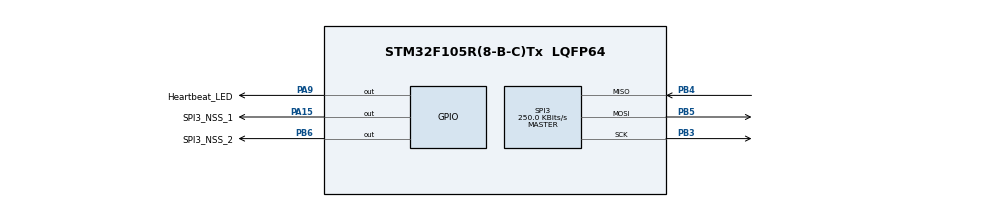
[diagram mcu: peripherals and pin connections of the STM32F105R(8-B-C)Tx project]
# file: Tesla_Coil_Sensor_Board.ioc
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Mcu.Family=STM32F1
Mcu.Name=STM32F105R(8-B-C)Tx
Mcu.Package=LQFP64
NVIC.PriorityGroup=NVIC_PRIORITYGROUP_4
NVIC.TIM2_IRQn=true\:0\:0\:false\:false\:true\:true\:true\:true
PA13.Mode=Serial_Wire
PA13.Signal=SYS_JTMS-SWDIO
PA14.Mode=Serial_Wire
PA14.Signal=SYS_JTCK-SWCLK
PA15.GPIO_Label=SPI3_NSS_1
PA15.Signal=GPIO_Output
PA9.GPIO_Label=Heartbeat_LED
PA9.Signal=GPIO_Output
PB3.Mode=Full_Duplex_Master
PB3.Signal=SPI3_SCK
PB4.Mode=Full_Duplex_Master
PB4.Signal=SPI3_MISO
PB5.Mode=Full_Duplex_Master
PB5.Signal=SPI3_MOSI
PB6.GPIO_Label=SPI3_NSS_2
PB6.Signal=GPIO_Output
ProjectManager.HeapSize=0x200
ProjectManager.StackSize=0x400
ProjectManager.TargetToolchain=STM32CubeIDE
RCC.USBFreq_Value=10666666.666666666
SPI3.BaudRatePrescaler=SPI_BAUDRATEPRESCALER_32
SPI3.CalculateBaudRate=250.0 KBits/s
SPI3.Direction=SPI_DIRECTION_2LINES
SPI3.Mode=SPI_MODE_MASTER
SPI3.VirtualType=VM_MASTER
TIM2.Period=1000 - 1
TIM2.Prescaler=8000 - 1
VP_TIM2_VS_ClockSourceINT.Mode=Internal
board=custom

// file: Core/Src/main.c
/* USER CODE BEGIN Header */
/**
  ******************************************************************************
  * @file           : main.c
  * @brief          : Main program body
  ******************************************************************************
  * @attention
  *
  * Copyright (c) 2025 STMicroelectronics.
  * All rights reserved.
  *
  * This software is licensed under terms that can be found in the LICENSE file
  * in the root directory of this software component.
  * If no LICENSE file comes with this software, it is provided AS-IS.
  *
  ******************************************************************************
  */
/* USER CODE END Header */
#include "main.h"

/* USER CODE BEGIN Includes */
#include "max31855.h"
#include <math.h>

/* USER CODE END Includes */

SPI_HandleTypeDef hspi3;

TIM_HandleTypeDef htim2;

void SystemClock_Config(void);
static void MX_GPIO_Init(void);
static void MX_TIM2_Init(void);
static void MX_SPI3_Init(void);

int main(void)
{

  /* USER CODE BEGIN 1 */
	float temperature = 0;
	int32_t temp_int = 0;

  /* USER CODE END 1 */

  /* MCU Configuration--------------------------------------------------------*/

  /* Reset of all peripherals, Initializes the Flash interface and the Systick. */
  HAL_Init();

  /* Configure the system clock */
  SystemClock_Config();

  /* Initialize all configured peripherals */
  MX_GPIO_Init();
  MX_TIM2_Init();
  MX_SPI3_Init();
  /* USER CODE BEGIN 2 */

  MAX31855_Init();					// Initialize the MAX31855;
  HAL_TIM_Base_Start_IT(&htim2);	// Start the interrupt timer

  /* USER CODE END 2 */

  /* Infinite loop */
  /* USER CODE BEGIN WHILE */
  while (1)
  {
	  // Read temperature from MAX31855
	  temperature = read_Temp();
	  temp_int = (int32_t)roundf(temperature);

    /* USER CODE END WHILE */

  }
}

void SystemClock_Config(void)
{
  RCC_OscInitTypeDef RCC_OscInitStruct = {0};
  RCC_ClkInitTypeDef RCC_ClkInitStruct = {0};

  /** Initializes the RCC Oscillators according to the specified parameters
  * in the RCC_OscInitTypeDef structure.
  */
  RCC_OscInitStruct.OscillatorType = RCC_OSCILLATORTYPE_HSI;
  RCC_OscInitStruct.HSIState = RCC_HSI_ON;
  RCC_OscInitStruct.HSICalibrationValue = RCC_HSICALIBRATION_DEFAULT;
  RCC_OscInitStruct.PLL.PLLState = RCC_PLL_NONE;
  RCC_OscInitStruct.PLL2.PLL2State = RCC_PLL_NONE;
  if (HAL_RCC_OscConfig(&RCC_OscInitStruct) != HAL_OK)
  {
    Error_Handler();
  }

  /** Initializes the CPU, AHB and APB buses clocks
  */
  RCC_ClkInitStruct.ClockType = RCC_CLOCKTYPE_HCLK|RCC_CLOCKTYPE_SYSCLK
                              |RCC_CLOCKTYPE_PCLK1|RCC_CLOCKTYPE_PCLK2;
  RCC_ClkInitStruct.SYSCLKSource = RCC_SYSCLKSOURCE_HSI;
  RCC_ClkInitStruct.AHBCLKDivider = RCC_SYSCLK_DIV1;
  RCC_ClkInitStruct.APB1CLKDivider = RCC_HCLK_DIV1;
  RCC_ClkInitStruct.APB2CLKDivider = RCC_HCLK_DIV1;

  if (HAL_RCC_ClockConfig(&RCC_ClkInitStruct, FLASH_LATENCY_0) != HAL_OK)
  {
    Error_Handler();
  }

  /** Configure the Systick interrupt time
  */
  __HAL_RCC_PLLI2S_ENABLE();
}

static void MX_SPI3_Init(void)
{

  /* SPI3 parameter configuration*/
  hspi3.Instance = SPI3;
  hspi3.Init.Mode = SPI_MODE_MASTER;
  hspi3.Init.Direction = SPI_DIRECTION_2LINES;
  hspi3.Init.DataSize = SPI_DATASIZE_8BIT;
  hspi3.Init.CLKPolarity = SPI_POLARITY_LOW;
  hspi3.Init.CLKPhase = SPI_PHASE_1EDGE;
  hspi3.Init.NSS = SPI_NSS_SOFT;
  hspi3.Init.BaudRatePrescaler = SPI_BAUDRATEPRESCALER_32;
  hspi3.Init.FirstBit = SPI_FIRSTBIT_MSB;
  hspi3.Init.TIMode = SPI_TIMODE_DISABLE;
  hspi3.Init.CRCCalculation = SPI_CRCCALCULATION_DISABLE;
  hspi3.Init.CRCPolynomial = 10;
  if (HAL_SPI_Init(&hspi3) != HAL_OK)
  {
    Error_Handler();
  }

}

static void MX_TIM2_Init(void)
{

  TIM_ClockConfigTypeDef sClockSourceConfig = {0};
  TIM_MasterConfigTypeDef sMasterConfig = {0};

  htim2.Instance = TIM2;
  htim2.Init.Prescaler = 8000 - 1;
  htim2.Init.CounterMode = TIM_COUNTERMODE_UP;
  htim2.Init.Period = 1000 - 1;
  htim2.Init.ClockDivision = TIM_CLOCKDIVISION_DIV1;
  htim2.Init.AutoReloadPreload = TIM_AUTORELOAD_PRELOAD_DISABLE;
  if (HAL_TIM_Base_Init(&htim2) != HAL_OK)
  {
    Error_Handler();
  }
  sClockSourceConfig.ClockSource = TIM_CLOCKSOURCE_INTERNAL;
  if (HAL_TIM_ConfigClockSource(&htim2, &sClockSourceConfig) != HAL_OK)
  {
    Error_Handler();
  }
  sMasterConfig.MasterOutputTrigger = TIM_TRGO_RESET;
  sMasterConfig.MasterSlaveMode = TIM_MASTERSLAVEMODE_DISABLE;
  if (HAL_TIMEx_MasterConfigSynchronization(&htim2, &sMasterConfig) != HAL_OK)
  {
    Error_Handler();
  }

}

static void MX_GPIO_Init(void)
{
  GPIO_InitTypeDef GPIO_InitStruct = {0};

  /* GPIO Ports Clock Enable */
  __HAL_RCC_GPIOA_CLK_ENABLE();
  __HAL_RCC_GPIOB_CLK_ENABLE();

  /*Configure GPIO pin Output Level */
  HAL_GPIO_WritePin(GPIOA, Heartbeat_LED_Pin|SPI3_NSS_1_Pin, GPIO_PIN_RESET);

  /*Configure GPIO pin Output Level */
  HAL_GPIO_WritePin(SPI3_NSS_2_GPIO_Port, SPI3_NSS_2_Pin, GPIO_PIN_RESET);

  /*Configure GPIO pins : Heartbeat_LED_Pin SPI3_NSS_1_Pin */
  GPIO_InitStruct.Pin = Heartbeat_LED_Pin|SPI3_NSS_1_Pin;
  GPIO_InitStruct.Mode = GPIO_MODE_OUTPUT_PP;
  GPIO_InitStruct.Pull = GPIO_NOPULL;
  GPIO_InitStruct.Speed = GPIO_SPEED_FREQ_LOW;
  HAL_GPIO_Init(GPIOA, &GPIO_InitStruct);

  /*Configure GPIO pin : SPI3_NSS_2_Pin */
  GPIO_InitStruct.Pin = SPI3_NSS_2_Pin;
  GPIO_InitStruct.Mode = GPIO_MODE_OUTPUT_PP;
  GPIO_InitStruct.Pull = GPIO_NOPULL;
  GPIO_InitStruct.Speed = GPIO_SPEED_FREQ_LOW;
  HAL_GPIO_Init(SPI3_NSS_2_GPIO_Port, &GPIO_InitStruct);

}

/* USER CODE BEGIN 4 */

// Callback: timer has rolled over
void HAL_TIM_PeriodElapsedCallback(TIM_HandleTypeDef *htim)
{
  // Check which version of the timer triggered this callback and toggle LED
  if (htim == &htim2 )
  {
//    HAL_GPIO_TogglePin(Heartbeat_LED_GPIO_Port, Heartbeat_LED_Pin);
  }
}

/* USER CODE END 4 */

void Error_Handler(void)
{
  __disable_irq();
  while (1)
  {
  }
}
